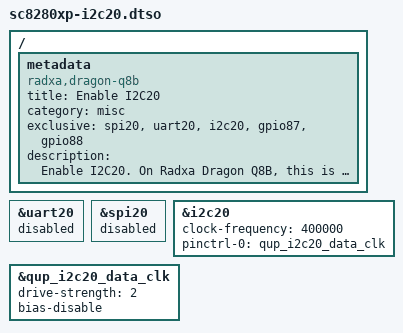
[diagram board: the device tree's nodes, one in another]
// SPDX-License-Identifier: BSD-3-Clause
/*
 * Copyright (c) 2026 Radxa Computer (Shenzhen) Co., Ltd.
 */

/dts-v1/;
/plugin/;

/ {
	metadata {
		title = "Enable I2C20";
		compatible = "radxa,dragon-q8b";
		category = "misc";
		exclusive = "spi20", "uart20", "i2c20", "gpio87", "gpio88";
		description = "Enable I2C20.
On Radxa Dragon Q8B, this is pin 19(scl), 21(sda).";
	};
};

&uart20 {
	status = "disabled";
};

&spi20 {
	status = "disabled";
};

&i2c20 {
	clock-frequency = <400000>;

	pinctrl-0 = <&qup_i2c20_data_clk>;
	pinctrl-names = "default";

	status = "okay";
};

&qup_i2c20_data_clk {
	drive-strength = <2>;
	bias-disable;
};
